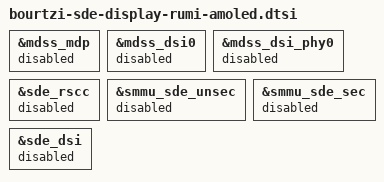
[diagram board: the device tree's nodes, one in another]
// SPDX-License-Identifier: BSD-3-Clause
/*
 * Copyright (c) Qualcomm Technologies, Inc. and/or its subsidiaries.
 */

#include "bourtzi-sde-display.dtsi"

&mdss_mdp {
	status = "disabled";
};

&mdss_dsi0 {
	status = "disabled";
};

&mdss_dsi_phy0 {
	status = "disabled";
};

&sde_rscc {
	status = "disabled";
};

&smmu_sde_unsec {
	status = "disabled";
};

&smmu_sde_sec {
	status = "disabled";
};

&sde_dsi {
	status = "disabled";
};
